VERSION ""

NS_ :

BS_:

BU_: Sensor_Node BMS_Controller Dashboard_Node

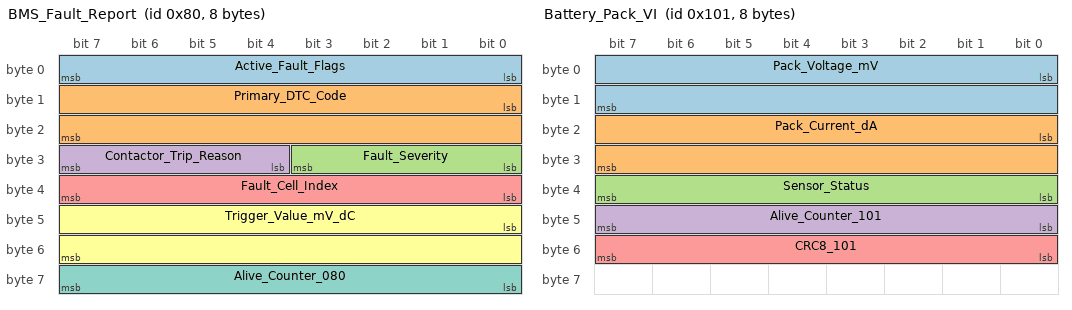
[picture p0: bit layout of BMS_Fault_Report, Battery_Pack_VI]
BO_ 128 BMS_Fault_Report: 8 BMS_Controller
 SG_ Active_Fault_Flags : 0|8@1+ (1,0) [0|255] "" Dashboard_Node
 SG_ Primary_DTC_Code : 8|16@1+ (1,0) [0|65535] "" Dashboard_Node
 SG_ Fault_Severity : 24|4@1+ (1,0) [0|3] "" Dashboard_Node
 SG_ Contactor_Trip_Reason : 28|4@1+ (1,0) [0|15] "" Dashboard_Node
 SG_ Fault_Cell_Index : 32|8@1+ (1,0) [0|4] "" Dashboard_Node
 SG_ Trigger_Value_mV_dC : 40|16@1- (1,0) [-32768|32767] "" Dashboard_Node
 SG_ Alive_Counter_080 : 56|8@1+ (1,0) [0|255] "" Dashboard_Node

BO_ 257 Battery_Pack_VI: 8 Sensor_Node
 SG_ Pack_Voltage_mV : 0|16@1+ (1,0) [0|65535] "mV" BMS_Controller,Dashboard_Node
 SG_ Pack_Current_dA : 16|16@1- (0.1,0) [-300|300] "A" BMS_Controller,Dashboard_Node
 SG_ Sensor_Status : 32|8@1+ (1,0) [0|255] "" BMS_Controller
 SG_ Alive_Counter_101 : 40|8@1+ (1,0) [0|255] "" BMS_Controller
 SG_ CRC8_101 : 48|8@1+ (1,0) [0|255] "" BMS_Controller

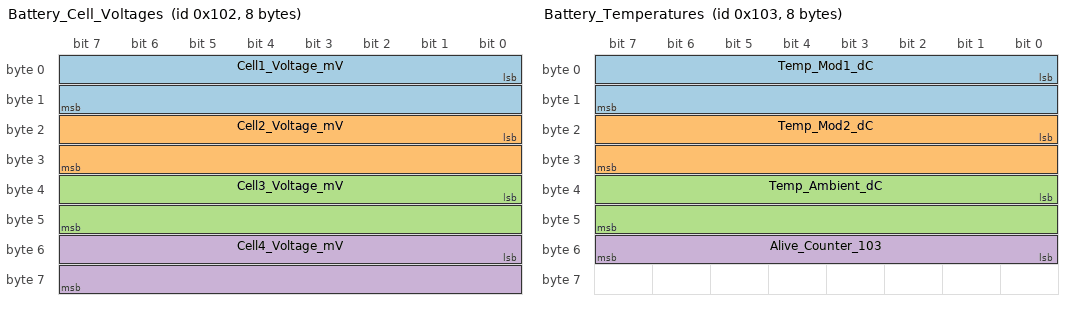
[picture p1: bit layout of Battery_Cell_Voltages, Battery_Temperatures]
BO_ 258 Battery_Cell_Voltages: 8 Sensor_Node
 SG_ Cell1_Voltage_mV : 0|16@1+ (1,0) [0|5000] "mV" BMS_Controller,Dashboard_Node
 SG_ Cell2_Voltage_mV : 16|16@1+ (1,0) [0|5000] "mV" BMS_Controller,Dashboard_Node
 SG_ Cell3_Voltage_mV : 32|16@1+ (1,0) [0|5000] "mV" BMS_Controller,Dashboard_Node
 SG_ Cell4_Voltage_mV : 48|16@1+ (1,0) [0|5000] "mV" BMS_Controller,Dashboard_Node

BO_ 259 Battery_Temperatures: 8 Sensor_Node
 SG_ Temp_Mod1_dC : 0|16@1- (0.1,0) [-40|125] "degC" BMS_Controller,Dashboard_Node
 SG_ Temp_Mod2_dC : 16|16@1- (0.1,0) [-40|125] "degC" BMS_Controller,Dashboard_Node
 SG_ Temp_Ambient_dC : 32|16@1- (0.1,0) [-40|125] "degC" BMS_Controller,Dashboard_Node
 SG_ Alive_Counter_103 : 48|8@1+ (1,0) [0|255] "" BMS_Controller

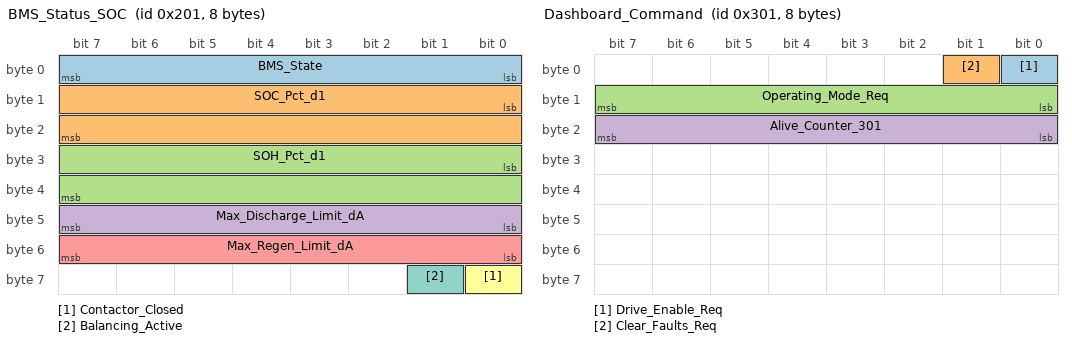
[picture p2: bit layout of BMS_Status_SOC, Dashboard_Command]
BO_ 513 BMS_Status_SOC: 8 BMS_Controller
 SG_ BMS_State : 0|8@1+ (1,0) [0|7] "" Dashboard_Node
 SG_ SOC_Pct_d1 : 8|16@1+ (0.1,0) [0|100] "%" Dashboard_Node
 SG_ SOH_Pct_d1 : 24|16@1+ (0.1,0) [0|100] "%" Dashboard_Node
 SG_ Max_Discharge_Limit_dA : 40|8@1+ (1,0) [0|250] "A" Dashboard_Node
 SG_ Max_Regen_Limit_dA : 48|8@1+ (1,0) [0|250] "A" Dashboard_Node
 SG_ Contactor_Closed : 56|1@1+ (1,0) [0|1] "" Dashboard_Node
 SG_ Balancing_Active : 57|1@1+ (1,0) [0|1] "" Dashboard_Node

BO_ 769 Dashboard_Command: 8 Dashboard_Node
 SG_ Drive_Enable_Req : 0|1@1+ (1,0) [0|1] "" BMS_Controller
 SG_ Clear_Faults_Req : 1|1@1+ (1,0) [0|1] "" BMS_Controller
 SG_ Operating_Mode_Req : 8|8@1+ (1,0) [0|3] "" BMS_Controller
 SG_ Alive_Counter_301 : 16|8@1+ (1,0) [0|255] "" BMS_Controller

CM_ BU_ Sensor_Node "Front-end Analog/Digital Battery Monitoring Unit (BMU) sampling cell voltages, pack current, and NTC thermistors";
CM_ BU_ BMS_Controller "Master Battery Management Controller executing SOC estimation, ISO 26262 safety diagnostics, and HV contactor control";
CM_ BU_ Dashboard_Node "Instrument Cluster & Supervisory HMI displaying pack telemetry, fault alerts, and operator commands";

VAL_ 513 BMS_State 0 "INIT" 1 "STANDBY" 2 "PRECHARGE" 3 "NORMAL_DRIVE" 4 "FAST_CHARGE" 5 "DERATING" 6 "FAULT_CUTOFF" ;
